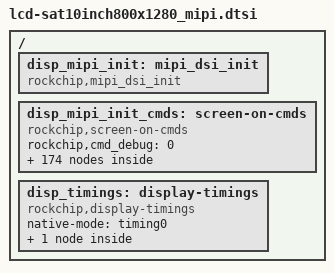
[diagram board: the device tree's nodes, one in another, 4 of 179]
/*
 * lcd model: fhd L7057ARRP051A
 * resolution: 1080 X 1920
 */
/*
 * arch/arm/boot/dts/lcd-sat10inch800x1280_mipi.dtsi
 * author: daniel
 * create date: 2017-05-26
 * lcd model: sat0101cp40I28R1-JD9366 
 * resolution: 800X1280
 * mipi channel: 4
 */
/ {
    /* about mipi */
    disp_mipi_init: mipi_dsi_init{
        compatible = "rockchip,mipi_dsi_init";
        rockchip,screen_init    = <1>;
        rockchip,dsi_lane       = <4>;
        rockchip,dsi_hs_clk     = <480>;
        rockchip,mipi_dsi_num   = <1>;
    };

/*
    disp_mipi_power_ctr: mipi_power_ctr {
        compatible = "rockchip,mipi_power_ctr";
        mipi_lcd_en:mipi_lcd_en {
                compatible = "rockchip,lcd_en";
                rockchip,gpios = <&gpio2 GPIO_B7 GPIO_ACTIVE_HIGH>;
                rockchip,delay = <20>;
        };
 
        mipi_lcd_rst:mipi_lcd_rst{
                compatible = "rockchip,lcd_rst";
                rockchip,gpios = <&gpio2 GPIO_B5 GPIO_ACTIVE_HIGH>;
                rockchip,delay = <50>;
        };
 
    };
    */

 	disp_mipi_init_cmds: screen-on-cmds {
			rockchip,cmd_debug = <0>;
			compatible = "rockchip,screen-on-cmds";
	         rockchip,on-cmds1{                                      
                                         compatible = "rockchip,on-cmds";  
                                         rockchip,cmd_type = <0x01>;     
                                         rockchip,dsi_id = <0>;          
                                         rockchip,cmd = <0x15 0xE0 0x00>;
                                         rockchip,cmd_delay = <0>;       
                                  };                                     
                 rockchip,on-cmds2{                                      
                                         compatible = "rockchip,on-cmds";  
                                         rockchip,cmd_type = <0x01>;     
                                         rockchip,dsi_id = <0>;          
                                         rockchip,cmd = <0x15 0xE1 0x93>;
                                         rockchip,cmd_delay = <0>;       
                                  };                                     
                 rockchip,on-cmds3{                                      
                                         compatible = "rockchip,on-cmds";  
                                         rockchip,cmd_type = <0x01>;     
                                         rockchip,dsi_id = <0>;          
                                         rockchip,cmd = <0x15 0xE2 0x65>;
                                         rockchip,cmd_delay = <0>;       
                                  };                                     
                 rockchip,on-cmds4{                                      
                                         compatible = "rockchip,on-cmds";  
                                         rockchip,cmd_type = <0x01>;     
                                         rockchip,dsi_id = <0>;          
                                         rockchip,cmd = <0x15 0xE3 0xF8>;
                                         rockchip,cmd_delay = <0>;       
                                  };                                     
                 rockchip,on-cmds5{                                      
                                         compatible = "rockchip,on-cmds";  
                                         rockchip,cmd_type = <0x01>;     
                                         rockchip,dsi_id = <0>;          
                                         rockchip,cmd = <0x15 0x80 0x03>;
                                         rockchip,cmd_delay = <0>;       
                                  };                                     
                 rockchip,on-cmds6{                                      
                                         compatible = "rockchip,on-cmds";  
                                         rockchip,cmd_type = <0x01>;     
                                         rockchip,dsi_id = <0>;          
                                         rockchip,cmd = <0x15 0xE0 0x04>;
                                         rockchip,cmd_delay = <0>;       
                                  };                                     
                 rockchip,on-cmds7{                                      
                                         compatible = "rockchip,on-cmds";  
                                         rockchip,cmd_type = <0x01>;     
                                         rockchip,dsi_id = <0>;          
                                         rockchip,cmd = <0x15 0x2D 0x03>;
                                         rockchip,cmd_delay = <0>;       
                                  };                                     
                 rockchip,on-cmds8{                                      
                                         compatible = "rockchip,on-cmds";  
                                         rockchip,cmd_type = <0x01>;     
                                         rockchip,dsi_id = <0>;          
                                         rockchip,cmd = <0x15 0x09 0x10>;
                                         rockchip,cmd_delay = <0>;       
                                  };  
	        rockchip,on-cmds175{                                      
                                         compatible = "rockchip,on-cmds";  
                                         rockchip,cmd_type = <0x01>;     
                                         rockchip,dsi_id = <0>;          
                                         rockchip,cmd = <0x15 0xE0 0x00>;
                                         rockchip,cmd_delay = <0>;       
                                  };                                     
                 rockchip,on-cmds9{                                      
                                         compatible = "rockchip,on-cmds";  
                                         rockchip,cmd_type = <0x01>;     
                                         rockchip,dsi_id = <0>;          
                                         rockchip,cmd = <0x15 0x70 0x10>;
                                         rockchip,cmd_delay = <0>;       
                                  };                                     
                 rockchip,on-cmds10{                                     
                                         compatible = "rockchip,on-cmds";  
                                         rockchip,cmd_type = <0x01>;     
                                         rockchip,dsi_id = <0>;          
                                         rockchip,cmd = <0x15 0x71 0x13>;
                                         rockchip,cmd_delay = <0>;       
                                  };                                     
                 rockchip,on-cmds11{                                     
                                         compatible = "rockchip,on-cmds";  
                                         rockchip,cmd_type = <0x01>;     
                                         rockchip,dsi_id = <0>;          
                                         rockchip,cmd = <0x15 0x72 0x06>;
                                         rockchip,cmd_delay = <0>;       
                                  };                                     
                 rockchip,on-cmds12{                                     
                                         compatible = "rockchip,on-cmds";  
                                         rockchip,cmd_type = <0x01>;     
                                         rockchip,dsi_id = <0>;          
                                         rockchip,cmd = <0x15 0xE0 0x02>;
                                         rockchip,cmd_delay = <0>;       
                                  };                                     
                 rockchip,on-cmds13{                                     
                                         compatible = "rockchip,on-cmds";  
                                         rockchip,cmd_type = <0x01>;     
                                         rockchip,dsi_id = <0>;          
                                         rockchip,cmd = <0x15 0x00 0x09>;
                                         rockchip,cmd_delay = <0>;       
                                  };                                     
                 rockchip,on-cmds14{                                     
                                         compatible = "rockchip,on-cmds";  
                                         rockchip,cmd_type = <0x01>;     
                                         rockchip,dsi_id = <0>;          
                                         rockchip,cmd = <0x15 0x01 0x05>;
                                         rockchip,cmd_delay = <0>;       
                                  };                                     
                 rockchip,on-cmds15{                                     
                                         compatible = "rockchip,on-cmds";  
                                         rockchip,cmd_type = <0x01>;     
                                         rockchip,dsi_id = <0>;          
                                         rockchip,cmd = <0x15 0x02 0x08>;
                                         rockchip,cmd_delay = <0>;       
                                  };                                     
                 rockchip,on-cmds16{                                     
                                         compatible = "rockchip,on-cmds";  
                                         rockchip,cmd_type = <0x01>;     
                                         rockchip,dsi_id = <0>;          
                                         rockchip,cmd = <0x15 0x03 0x04>;
                                         rockchip,cmd_delay = <0>;       
                                  };                                     
                 rockchip,on-cmds17{                                     
                                         compatible = "rockchip,on-cmds";  
                                         rockchip,cmd_type = <0x01>;     
                                         rockchip,dsi_id = <0>;          
                                         rockchip,cmd = <0x15 0x04 0x06>;
                                         rockchip,cmd_delay = <0>;       
                                  };                                     
                 rockchip,on-cmds18{                                     
                                         compatible = "rockchip,on-cmds";  
                                         rockchip,cmd_type = <0x01>;     
                                         rockchip,dsi_id = <0>;          
                                         rockchip,cmd = <0x15 0x05 0x0A>;
                                         rockchip,cmd_delay = <0>;       
                                  };                                     
                 rockchip,on-cmds19{                                     
                                         compatible = "rockchip,on-cmds";  
                                         rockchip,cmd_type = <0x01>;     
                                         rockchip,dsi_id = <0>;          
                                         rockchip,cmd = <0x15 0x06 0x07>;
                                         rockchip,cmd_delay = <0>;       
                                  };                                     
                 rockchip,on-cmds20{                                     
                                         compatible = "rockchip,on-cmds";  
                                         rockchip,cmd_type = <0x01>;     
                                         rockchip,dsi_id = <0>;          
                                         rockchip,cmd = <0x15 0x07 0x0B>;
                                         rockchip,cmd_delay = <0>;       
                                  };                                     
                 rockchip,on-cmds21{                                     
                                         compatible = "rockchip,on-cmds";  
                                         rockchip,cmd_type = <0x01>;     
                                         rockchip,dsi_id = <0>;          
                                         rockchip,cmd = <0x15 0x08 0x00>;
                                         rockchip,cmd_delay = <0>;       
                                  };                                     
                 rockchip,on-cmds22{                                     
                                         compatible = "rockchip,on-cmds";  
                                         rockchip,cmd_type = <0x01>;     
                                         rockchip,dsi_id = <0>;          
                                         rockchip,cmd = <0x15 0x09 0x1F>;
                                         rockchip,cmd_delay = <0>;       
                                  };                                     
                 rockchip,on-cmds23{                                     
                                         compatible = "rockchip,on-cmds";  
                                         rockchip,cmd_type = <0x01>;     
                                         rockchip,dsi_id = <0>;          
                                         rockchip,cmd = <0x15 0x0A 0x1F>;
                                         rockchip,cmd_delay = <0>;       
                                  };                                     
                 rockchip,on-cmds24{                                     
                                         compatible = "rockchip,on-cmds";  
                                         rockchip,cmd_type = <0x01>;     
                                         rockchip,dsi_id = <0>;          
                                         rockchip,cmd = <0x15 0x0C 0x1F>;
                                         rockchip,cmd_delay = <0>;       
                                  };                                     
                 rockchip,on-cmds25{                                     
                                         compatible = "rockchip,on-cmds";  
                                         rockchip,cmd_type = <0x01>;     
                                         rockchip,dsi_id = <0>;          
                                         rockchip,cmd = <0x15 0x0D 0x1F>;
                                         rockchip,cmd_delay = <0>;       
                                  };                                     
                 rockchip,on-cmds26{                                     
                                         compatible = "rockchip,on-cmds";  
                                         rockchip,cmd_type = <0x01>;     
                                         rockchip,dsi_id = <0>;          
                                         rockchip,cmd = <0x15 0x0E 0x1F>;
                                         rockchip,cmd_delay = <0>;       
                                  };                                     
                 rockchip,on-cmds27{                                     
                                         compatible = "rockchip,on-cmds";  
                                         rockchip,cmd_type = <0x01>;     
                                         rockchip,dsi_id = <0>;          
                                         rockchip,cmd = <0x15 0x0F 0x17>;
                                         rockchip,cmd_delay = <0>;       
                                  };                                     
                 rockchip,on-cmds28{                                     
                                         compatible = "rockchip,on-cmds";  
                                         rockchip,cmd_type = <0x01>;     
                                         rockchip,dsi_id = <0>;          
                                         rockchip,cmd = <0x15 0x10 0x37>;
                                         rockchip,cmd_delay = <0>;       
                                  };                                     
                 rockchip,on-cmds29{                                     
                                         compatible = "rockchip,on-cmds";  
                                         rockchip,cmd_type = <0x01>;     
                                         rockchip,dsi_id = <0>;          
                                         rockchip,cmd = <0x15 0x11 0x1F>;
                                         rockchip,cmd_delay = <0>;       
                                  };                                     
                 rockchip,on-cmds30{                                     
                                         compatible = "rockchip,on-cmds";  
                                         rockchip,cmd_type = <0x01>;     
                                         rockchip,dsi_id = <0>;          
                                         rockchip,cmd = <0x15 0x12 0x1F>;
                                         rockchip,cmd_delay = <0>;       
                                  };                                     
                 rockchip,on-cmds31{                                     
                                         compatible = "rockchip,on-cmds";  
                                         rockchip,cmd_type = <0x01>;     
                                         rockchip,dsi_id = <0>;          
                                         rockchip,cmd = <0x15 0x13 0x1E>;
                                         rockchip,cmd_delay = <0>;       
                                  };                                     
                 rockchip,on-cmds32{                                     
                                         compatible = "rockchip,on-cmds";  
                                         rockchip,cmd_type = <0x01>;     
                                         rockchip,dsi_id = <0>;          
                                         rockchip,cmd = <0x15 0x14 0x10>;
                                         rockchip,cmd_delay = <0>;       
                                  };                                     
                 rockchip,on-cmds33{                                     
                                         compatible = "rockchip,on-cmds";  
                                         rockchip,cmd_type = <0x01>;     
                                         rockchip,dsi_id = <0>;          
                                         rockchip,cmd = <0x15 0x15 0x1F>;
                                         rockchip,cmd_delay = <0>;       
                                  };                                     
                 rockchip,on-cmds34{                                     
                                         compatible = "rockchip,on-cmds";  
                                         rockchip,cmd_type = <0x01>;     
                                         rockchip,dsi_id = <0>;          
                                         rockchip,cmd = <0x15 0x16 0x09>;
                                         rockchip,cmd_delay = <0>;       
                                  };                                     
                 rockchip,on-cmds35{                                     
                                         compatible = "rockchip,on-cmds";  
                                         rockchip,cmd_type = <0x01>;     
                                         rockchip,dsi_id = <0>;          
                                         rockchip,cmd = <0x15 0x17 0x05>;
                                         rockchip,cmd_delay = <0>;       
                                  };                                     
                 rockchip,on-cmds36{                                     
                                         compatible = "rockchip,on-cmds";  
                                         rockchip,cmd_type = <0x01>;     
                                         rockchip,dsi_id = <0>;          
                                         rockchip,cmd = <0x15 0x18 0x08>;
                                         rockchip,cmd_delay = <0>;       
                                  };                                     
                 rockchip,on-cmds37{                                     
                                         compatible = "rockchip,on-cmds";  
                                         rockchip,cmd_type = <0x01>;     
                                         rockchip,dsi_id = <0>;          
                                         rockchip,cmd = <0x15 0x19 0x04>;
                                         rockchip,cmd_delay = <0>;       
                                  };                                     
                 rockchip,on-cmds38{                                     
                                         compatible = "rockchip,on-cmds";  
                                         rockchip,cmd_type = <0x01>;     
                                         rockchip,dsi_id = <0>;          
                                         rockchip,cmd = <0x15 0x1A 0x06>;
                                         rockchip,cmd_delay = <0>;       
                                  };                                     
                 rockchip,on-cmds39{                                     
                                         compatible = "rockchip,on-cmds";  
                                         rockchip,cmd_type = <0x01>;     
                                         rockchip,dsi_id = <0>;          
                                         rockchip,cmd = <0x15 0x1B 0x0A>;
                                         rockchip,cmd_delay = <0>;       
                                  };                                     
                 rockchip,on-cmds40{                                     
                                         compatible = "rockchip,on-cmds";  
                                         rockchip,cmd_type = <0x01>;     
                                         rockchip,dsi_id = <0>;          
                                         rockchip,cmd = <0x15 0x1C 0x07>;
                                         rockchip,cmd_delay = <0>;       
                                  };                                     
                 rockchip,on-cmds41{                                     
                                         compatible = "rockchip,on-cmds";  
                                         rockchip,cmd_type = <0x01>;     
                                         rockchip,dsi_id = <0>;          
                                         rockchip,cmd = <0x15 0x1D 0x0B>;
                                         rockchip,cmd_delay = <0>;       
                                  };                                     
                 rockchip,on-cmds42{                                     
                                         compatible = "rockchip,on-cmds";  
                                         rockchip,cmd_type = <0x01>;     
                                         rockchip,dsi_id = <0>;          
                                         rockchip,cmd = <0x15 0x1E 0x00>;
                                         rockchip,cmd_delay = <0>;       
                                  };                                     
                 rockchip,on-cmds43{                                     
                                         compatible = "rockchip,on-cmds";  
                                         rockchip,cmd_type = <0x01>;     
                                         rockchip,dsi_id = <0>;          
                                         rockchip,cmd = <0x15 0x1F 0x1F>;
                                         rockchip,cmd_delay = <0>;       
                                  };                                     
                 rockchip,on-cmds44{                                     
                                         compatible = "rockchip,on-cmds";  
                                         rockchip,cmd_type = <0x01>;     
                                         rockchip,dsi_id = <0>;          
                                         rockchip,cmd = <0x15 0x20 0x1F>;
                                         rockchip,cmd_delay = <0>;       
                                  };                                     
                 rockchip,on-cmds45{                                     
                                         compatible = "rockchip,on-cmds";  
                                         rockchip,cmd_type = <0x01>;     
                                         rockchip,dsi_id = <0>;          
                                         rockchip,cmd = <0x15 0x21 0x1F>;
                                         rockchip,cmd_delay = <0>;       
                                  };                                     
                 rockchip,on-cmds46{                                     
                                         compatible = "rockchip,on-cmds";  
                                         rockchip,cmd_type = <0x01>;     
                                         rockchip,dsi_id = <0>;          
                                         rockchip,cmd = <0x15 0x22 0x1F>;
                                         rockchip,cmd_delay = <0>;       
                                  };                                     
                 rockchip,on-cmds47{                                     
                                         compatible = "rockchip,on-cmds";  
                                         rockchip,cmd_type = <0x01>;     
                                         rockchip,dsi_id = <0>;          
                                         rockchip,cmd = <0x15 0x23 0x1F>;
                                         rockchip,cmd_delay = <0>;       
                                  };                                     
                 rockchip,on-cmds48{                                     
                                         compatible = "rockchip,on-cmds";  
                                         rockchip,cmd_type = <0x01>;     
                                         rockchip,dsi_id = <0>;          
                                         rockchip,cmd = <0x15 0x24 0x1F>;
                                         rockchip,cmd_delay = <0>;       
                                  };                                     
                 rockchip,on-cmds49{                                     
                                         compatible = "rockchip,on-cmds";  
                                         rockchip,cmd_type = <0x01>;     
                                         rockchip,dsi_id = <0>;          
                                         rockchip,cmd = <0x15 0x25 0x17>;
                                         rockchip,cmd_delay = <0>;       
                                  };                                     
                 rockchip,on-cmds50{                                     
                                         compatible = "rockchip,on-cmds";  
                                         rockchip,cmd_type = <0x01>;     
                                         rockchip,dsi_id = <0>;          
                                         rockchip,cmd = <0x15 0x26 0x37>;
                                         rockchip,cmd_delay = <0>;       
                                  };                                     
                 rockchip,on-cmds51{                                     
                                         compatible = "rockchip,on-cmds";  
                                         rockchip,cmd_type = <0x01>;     
                                         rockchip,dsi_id = <0>;          
                                         rockchip,cmd = <0x15 0x27 0x1F>;
                                         rockchip,cmd_delay = <0>;       
                                  };                                     
                 rockchip,on-cmds52{                                     
                                         compatible = "rockchip,on-cmds";  
                                         rockchip,cmd_type = <0x01>;     
                                         rockchip,dsi_id = <0>;          
                                         rockchip,cmd = <0x15 0x28 0x1F>;
                                         rockchip,cmd_delay = <0>;       
                                  };                                     
                 rockchip,on-cmds53{                                     
                                         compatible = "rockchip,on-cmds";  
                                         rockchip,cmd_type = <0x01>;     
                                         rockchip,dsi_id = <0>;          
                                         rockchip,cmd = <0x15 0x29 0x1E>;
                                         rockchip,cmd_delay = <0>;       
                                  };                                     
                 rockchip,on-cmds54{                                     
                                         compatible = "rockchip,on-cmds";  
                                         rockchip,cmd_type = <0x01>;     
                                         rockchip,dsi_id = <0>;          
                                         rockchip,cmd = <0x15 0x2A 0x10>;
                                         rockchip,cmd_delay = <0>;       
                                  };                                     
                 rockchip,on-cmds55{                                     
                                         compatible = "rockchip,on-cmds";  
                                         rockchip,cmd_type = <0x01>;     
                                         rockchip,dsi_id = <0>;          
                                         rockchip,cmd = <0x15 0x2B 0x1F>;
                                         rockchip,cmd_delay = <0>;       
                                  };                                     
                 rockchip,on-cmds56{                                     
                                         compatible = "rockchip,on-cmds";  
                                         rockchip,cmd_type = <0x01>;     
                                         rockchip,dsi_id = <0>;          
                                         rockchip,cmd = <0x15 0x58 0x01>;
                                         rockchip,cmd_delay = <0>;       
                                  };                                     
                 rockchip,on-cmds57{                                     
                                         compatible = "rockchip,on-cmds";  
                                         rockchip,cmd_type = <0x01>;     
                                         rockchip,dsi_id = <0>;          
                                         rockchip,cmd = <0x15 0x59 0x00>;
                                         rockchip,cmd_delay = <0>;       
                                  };                                     
                 rockchip,on-cmds58{                                     
                                         compatible = "rockchip,on-cmds";  
                                         rockchip,cmd_type = <0x01>;     
                                         rockchip,dsi_id = <0>;          
                                         rockchip,cmd = <0x15 0x5A 0x00>;
                                         rockchip,cmd_delay = <0>;       
                                  };                                     
                 rockchip,on-cmds59{                                     
                                         compatible = "rockchip,on-cmds";  
                                         rockchip,cmd_type = <0x01>;     
                                         rockchip,dsi_id = <0>;          
                                         rockchip,cmd = <0x15 0x5B 0x00>;
                                         rockchip,cmd_delay = <0>;       
                                  };                                     
                 rockchip,on-cmds60{                                     
                                         compatible = "rockchip,on-cmds";  
                                         rockchip,cmd_type = <0x01>;     
                                         rockchip,dsi_id = <0>;          
                                         rockchip,cmd = <0x15 0x5C 0x01>;
                                         rockchip,cmd_delay = <0>;       
                                  };                                     
                 rockchip,on-cmds61{                                     
                                         compatible = "rockchip,on-cmds";  
                                         rockchip,cmd_type = <0x01>;     
                                         rockchip,dsi_id = <0>;          
                                         rockchip,cmd = <0x15 0x5D 0x70>;
                                         rockchip,cmd_delay = <0>;       
                                  };                                     
                 rockchip,on-cmds62{                                     
                                         compatible = "rockchip,on-cmds";  
                                         rockchip,cmd_type = <0x01>;     
                                         rockchip,dsi_id = <0>;          
                                         rockchip,cmd = <0x15 0x5E 0x00>;
                                         rockchip,cmd_delay = <0>;       
                                  };                                     
                 rockchip,on-cmds63{                                     
                                         compatible = "rockchip,on-cmds";  
                                         rockchip,cmd_type = <0x01>;     
                                         rockchip,dsi_id = <0>;          
                                         rockchip,cmd = <0x15 0x5F 0x00>;
                                         rockchip,cmd_delay = <0>;       
                                  };                                     
                 rockchip,on-cmds64{                                     
                                         compatible = "rockchip,on-cmds";  
                                         rockchip,cmd_type = <0x01>;     
                                         rockchip,dsi_id = <0>;          
                                         rockchip,cmd = <0x15 0x60 0x40>;
                                         rockchip,cmd_delay = <0>;       
                                  };                                     
                 rockchip,on-cmds65{                                     
                                         compatible = "rockchip,on-cmds";  
                                         rockchip,cmd_type = <0x01>;     
                                         rockchip,dsi_id = <0>;          
                                         rockchip,cmd = <0x15 0x61 0x00>;
                                         rockchip,cmd_delay = <0>;       
                                  };                                     
                 rockchip,on-cmds66{                                     
                                         compatible = "rockchip,on-cmds";  
                                         rockchip,cmd_type = <0x01>;     
                                         rockchip,dsi_id = <0>;          
                                         rockchip,cmd = <0x15 0x62 0x00>;
                                         rockchip,cmd_delay = <0>;       
                                  };                                     
                 rockchip,on-cmds67{                                     
                                         compatible = "rockchip,on-cmds";  
                                         rockchip,cmd_type = <0x01>;     
                                         rockchip,dsi_id = <0>;          
                                         rockchip,cmd = <0x15 0x63 0x65>;
                                         rockchip,cmd_delay = <0>;       
                                  };                                     
                 rockchip,on-cmds68{                                     
                                         compatible = "rockchip,on-cmds";  
                                         rockchip,cmd_type = <0x01>;     
                                         rockchip,dsi_id = <0>;          
                                         rockchip,cmd = <0x15 0x64 0x65>;
                                         rockchip,cmd_delay = <0>;       
                                  };                                     
                 rockchip,on-cmds69{                                     
                                         compatible = "rockchip,on-cmds";  
                                         rockchip,cmd_type = <0x01>;     
                                         rockchip,dsi_id = <0>;          
                                         rockchip,cmd = <0x15 0x65 0x45>;
                                         rockchip,cmd_delay = <0>;       
                                  };                                     
                 rockchip,on-cmds70{                                     
                                         compatible = "rockchip,on-cmds";  
                                         rockchip,cmd_type = <0x01>;     
                                         rockchip,dsi_id = <0>;          
                                         rockchip,cmd = <0x15 0x66 0x09>;
                                         rockchip,cmd_delay = <0>;       
                                  };                                     
                 rockchip,on-cmds71{                                     
                                         compatible = "rockchip,on-cmds";  
                                         rockchip,cmd_type = <0x01>;     
                                         rockchip,dsi_id = <0>;          
                                         rockchip,cmd = <0x15 0x67 0x73>;
                                         rockchip,cmd_delay = <0>;       
                                  };                                     
                 rockchip,on-cmds72{                                     
                                         compatible = "rockchip,on-cmds";  
                                         rockchip,cmd_type = <0x01>;     
                                         rockchip,dsi_id = <0>;          
                                         rockchip,cmd = <0x15 0x68 0x05>;
                                         rockchip,cmd_delay = <0>;       
                                  };                                     
                 rockchip,on-cmds73{                                     
                                         compatible = "rockchip,on-cmds";  
                                         rockchip,cmd_type = <0x01>;     
                                         rockchip,dsi_id = <0>;          
                                         rockchip,cmd = <0x15 0x69 0x00>;
                                         rockchip,cmd_delay = <0>;       
                                  };                                     
                 rockchip,on-cmds74{                                     
                                         compatible = "rockchip,on-cmds";  
                                         rockchip,cmd_type = <0x01>;     
                                         rockchip,dsi_id = <0>;          
                                         rockchip,cmd = <0x15 0x6A 0x64>;
                                         rockchip,cmd_delay = <0>;       
                                  };                                     
                 rockchip,on-cmds75{                                     
                                         compatible = "rockchip,on-cmds";  
                                         rockchip,cmd_type = <0x01>;     
                                         rockchip,dsi_id = <0>;          
                                         rockchip,cmd = <0x15 0x6B 0x00>;
                                         rockchip,cmd_delay = <0>;       
                                  };                                     
                 rockchip,on-cmds76{                                     
                                         compatible = "rockchip,on-cmds";  
                                         rockchip,cmd_type = <0x01>;     
                                         rockchip,dsi_id = <0>;          
                                         rockchip,cmd = <0x15 0x6C 0x00>;
                                         rockchip,cmd_delay = <0>;       
                                  };                                     
                 rockchip,on-cmds77{                                     
                                         compatible = "rockchip,on-cmds";  
                                         rockchip,cmd_type = <0x01>;     
                                         rockchip,dsi_id = <0>;          
                                         rockchip,cmd = <0x15 0x6D 0x00>;
                                         rockchip,cmd_delay = <0>;       
                                  };                                     
                 rockchip,on-cmds78{                                     
                                         compatible = "rockchip,on-cmds";  
                                         rockchip,cmd_type = <0x01>;     
                                         rockchip,dsi_id = <0>;          
                                         rockchip,cmd = <0x15 0x6E 0x00>;
                                         rockchip,cmd_delay = <0>;       
                                  };                                     
                 rockchip,on-cmds79{                                     
                                         compatible = "rockchip,on-cmds";  
                                         rockchip,cmd_type = <0x01>;     
                                         rockchip,dsi_id = <0>;          
                                         rockchip,cmd = <0x15 0x6F 0x88>;
                                         rockchip,cmd_delay = <0>;       
                                  };                                     
                 rockchip,on-cmds80{                                     
                                         compatible = "rockchip,on-cmds";  
                                         rockchip,cmd_type = <0x01>;     
                                         rockchip,dsi_id = <0>;          
                                         rockchip,cmd = <0x15 0x70 0x00>;
                                         rockchip,cmd_delay = <0>;       
                                  };                                     
                 rockchip,on-cmds81{                                     
                                         compatible = "rockchip,on-cmds";  
                                         rockchip,cmd_type = <0x01>;     
                                         rockchip,dsi_id = <0>;          
                                         rockchip,cmd = <0x15 0x71 0x00>;
                                         rockchip,cmd_delay = <0>;       
                                  };                                     
                 rockchip,on-cmds82{                                     
                                         compatible = "rockchip,on-cmds";  
                                         rockchip,cmd_type = <0x01>;     
                                         rockchip,dsi_id = <0>;          
                                         rockchip,cmd = <0x15 0x72 0x06>;
                                         rockchip,cmd_delay = <0>;       
                                  };                                     
                 rockchip,on-cmds83{                                     
                                         compatible = "rockchip,on-cmds";  
                                         rockchip,cmd_type = <0x01>;     
                                         rockchip,dsi_id = <0>;          
                                         rockchip,cmd = <0x15 0x73 0x7B>;
                                         rockchip,cmd_delay = <0>;       
                                  };                                     
                 rockchip,on-cmds84{                                     
                                         compatible = "rockchip,on-cmds";  
                                         rockchip,cmd_type = <0x01>;     
                                         rockchip,dsi_id = <0>;          
                                         rockchip,cmd = <0x15 0x74 0x00>;
                                         rockchip,cmd_delay = <0>;       
                                  };                                     
                 rockchip,on-cmds85{                                     
                                         compatible = "rockchip,on-cmds";  
                                         rockchip,cmd_type = <0x01>;     
                                         rockchip,dsi_id = <0>;          
                                         rockchip,cmd = <0x15 0x75 0x80>;
                                         rockchip,cmd_delay = <0>;       
                                  };                                     
                 rockchip,on-cmds86{                                     
                                         compatible = "rockchip,on-cmds";  
                                         rockchip,cmd_type = <0x01>;     
                                         rockchip,dsi_id = <0>;          
                                         rockchip,cmd = <0x15 0x76 0x00>;
                                         rockchip,cmd_delay = <0>;       
                                  };                                     
                 rockchip,on-cmds87{                                     
                                         compatible = "rockchip,on-cmds";  
                                         rockchip,cmd_type = <0x01>;     
                                         rockchip,dsi_id = <0>;          
                                         rockchip,cmd = <0x15 0x77 0x05>;
                                         rockchip,cmd_delay = <0>;       
                                  };                                     
                 rockchip,on-cmds88{                                     
                                         compatible = "rockchip,on-cmds";  
                                         rockchip,cmd_type = <0x01>;     
                                         rockchip,dsi_id = <0>;          
                                         rockchip,cmd = <0x15 0x78 0x18>;
                                         rockchip,cmd_delay = <0>;       
                                  };                                     
                 rockchip,on-cmds89{                                     
                                         compatible = "rockchip,on-cmds";  
                                         rockchip,cmd_type = <0x01>;     
                                         rockchip,dsi_id = <0>;          
                                         rockchip,cmd = <0x15 0x79 0x00>;
                                         rockchip,cmd_delay = <0>;       
                                  };                                     
                 rockchip,on-cmds90{                                     
                                         compatible = "rockchip,on-cmds";  
                                         rockchip,cmd_type = <0x01>;     
                                         rockchip,dsi_id = <0>;          
                                         rockchip,cmd = <0x15 0x7A 0x00>;
                                         rockchip,cmd_delay = <0>;       
                                  };                                     
                 rockchip,on-cmds91{                                     
                                         compatible = "rockchip,on-cmds";  
                                         rockchip,cmd_type = <0x01>;     
                                         rockchip,dsi_id = <0>;          
                                         rockchip,cmd = <0x15 0x7B 0x00>;
                                         rockchip,cmd_delay = <0>;       
                                  };                                     
                 rockchip,on-cmds92{                                     
                                         compatible = "rockchip,on-cmds";  
                                         rockchip,cmd_type = <0x01>;     
                                         rockchip,dsi_id = <0>;          
                                         rockchip,cmd = <0x15 0x7C 0x00>;
                                         rockchip,cmd_delay = <0>;       
                                  };                                     
                 rockchip,on-cmds93{                                     
                                         compatible = "rockchip,on-cmds";  
                                         rockchip,cmd_type = <0x01>;     
                                         rockchip,dsi_id = <0>;          
                                         rockchip,cmd = <0x15 0x7D 0x03>;
                                         rockchip,cmd_delay = <0>;       
                                  };                                     
                 rockchip,on-cmds94{                                     
                                         compatible = "rockchip,on-cmds";  
                                         rockchip,cmd_type = <0x01>;     
                                         rockchip,dsi_id = <0>;          
                                         rockchip,cmd = <0x15 0x7E 0x7B>;
                                         rockchip,cmd_delay = <0>;       
                                  };                                     
                 rockchip,on-cmds95{                                     
                                         compatible = "rockchip,on-cmds";  
                                         rockchip,cmd_type = <0x01>;     
                                         rockchip,dsi_id = <0>;          
                                         rockchip,cmd = <0x15 0xE0 0x01>;
                                         rockchip,cmd_delay = <0>;       
                                  };                                     
                 rockchip,on-cmds96{                                     
                                         compatible = "rockchip,on-cmds";  
                                         rockchip,cmd_type = <0x01>;     
                                         rockchip,dsi_id = <0>;          
                                         rockchip,cmd = <0x15 0x00 0x00>;
                                         rockchip,cmd_delay = <0>;       
                                  };                                     
                 rockchip,on-cmds97{                                     
                                         compatible = "rockchip,on-cmds";  
                                         rockchip,cmd_type = <0x01>;     
                                         rockchip,dsi_id = <0>;          
                                         rockchip,cmd = <0x15 0x01 0x7B>;
                                         rockchip,cmd_delay = <0>;       
                                  };                                     
                 rockchip,on-cmds98{                                     
                                         compatible = "rockchip,on-cmds";  
                                         rockchip,cmd_type = <0x01>;     
                                         rockchip,dsi_id = <0>;          
                                         rockchip,cmd = <0x15 0x17 0x00>;
                                         rockchip,cmd_delay = <0>;       
                                  };                                     
                 rockchip,on-cmds99{                                     
                                         compatible = "rockchip,on-cmds";  
                                         rockchip,cmd_type = <0x01>;     
                                         rockchip,dsi_id = <0>;          
                                         rockchip,cmd = <0x15 0x18 0xC2>;
                                         rockchip,cmd_delay = <0>;       
                                  };                                     
                 rockchip,on-cmds100{                                    
                                         compatible = "rockchip,on-cmds";  
                                         rockchip,cmd_type = <0x01>;     
                                         rockchip,dsi_id = <0>;          
                                         rockchip,cmd = <0x15 0x19 0x01>;
                                         rockchip,cmd_delay = <0>;       
                                  };                                     
                 rockchip,on-cmds101{                                    
                                         compatible = "rockchip,on-cmds";  
                                         rockchip,cmd_type = <0x01>;     
                                         rockchip,dsi_id = <0>;          
                                         rockchip,cmd = <0x15 0x1A 0x00>;
                                         rockchip,cmd_delay = <0>;       
                                  };                                     
                 rockchip,on-cmds102{                                    
                                         compatible = "rockchip,on-cmds";  
                                         rockchip,cmd_type = <0x01>;     
                                         rockchip,dsi_id = <0>;          
                                         rockchip,cmd = <0x15 0x1B 0xC2>;
                                         rockchip,cmd_delay = <0>;       
                                  };                                     
                 rockchip,on-cmds103{                                    
                                         compatible = "rockchip,on-cmds";  
                                         rockchip,cmd_type = <0x01>;     
                                         rockchip,dsi_id = <0>;          
                                         rockchip,cmd = <0x15 0x1C 0x01>;
                                         rockchip,cmd_delay = <0>;       
                                  };                                     
                 rockchip,on-cmds104{                                    
                                         compatible = "rockchip,on-cmds";  
                                         rockchip,cmd_type = <0x01>;     
                                         rockchip,dsi_id = <0>;          
                                         rockchip,cmd = <0x15 0x1F 0x3F>;
                                         rockchip,cmd_delay = <0>;       
                                  };                                     
                 rockchip,on-cmds105{                                    
                                         compatible = "rockchip,on-cmds";  
                                         rockchip,cmd_type = <0x01>;     
                                         rockchip,dsi_id = <0>;          
                                         rockchip,cmd = <0x15 0x20 0x24>;
                                         rockchip,cmd_delay = <0>;       
                                  };                                     
                 rockchip,on-cmds106{                                    
                                         compatible = "rockchip,on-cmds";  
                                         rockchip,cmd_type = <0x01>;     
                                         rockchip,dsi_id = <0>;          
                                         rockchip,cmd = <0x15 0x21 0x24>;
                                         rockchip,cmd_delay = <0>;       
                                  };                                     
                 rockchip,on-cmds107{                                    
                                         compatible = "rockchip,on-cmds";  
                                         rockchip,cmd_type = <0x01>;     
                                         rockchip,dsi_id = <0>;          
                                         rockchip,cmd = <0x15 0x22 0x0E>;
                                         rockchip,cmd_delay = <0>;       
                                  };                                     
                 rockchip,on-cmds108{                                    
                                         compatible = "rockchip,on-cmds";  
                                         rockchip,cmd_type = <0x01>;     
                                         rockchip,dsi_id = <0>;          
                                         rockchip,cmd = <0x15 0x37 0x09>;
                                         rockchip,cmd_delay = <0>;       
                                  };                                     
                 rockchip,on-cmds109{                                    
                                         compatible = "rockchip,on-cmds";  
                                         rockchip,cmd_type = <0x01>;     
                                         rockchip,dsi_id = <0>;          
                                         rockchip,cmd = <0x15 0x38 0x04>;
                                         rockchip,cmd_delay = <0>;       
                                  };                                     
                 rockchip,on-cmds110{                                    
                                         compatible = "rockchip,on-cmds";  
                                         rockchip,cmd_type = <0x01>;     
                                         rockchip,dsi_id = <0>;          
                                         rockchip,cmd = <0x15 0x39 0x00>;
                                         rockchip,cmd_delay = <0>;       
                                  };                                     
                 rockchip,on-cmds111{                                    
                                         compatible = "rockchip,on-cmds";  
                                         rockchip,cmd_type = <0x01>;     
                                         rockchip,dsi_id = <0>;          
                                         rockchip,cmd = <0x15 0x3A 0x01>;
                                         rockchip,cmd_delay = <0>;       
                                  };                                     
                 rockchip,on-cmds112{                                    
                                         compatible = "rockchip,on-cmds";  
                                         rockchip,cmd_type = <0x01>;     
                                         rockchip,dsi_id = <0>;          
                                         rockchip,cmd = <0x15 0x3C 0x78>;
                                         rockchip,cmd_delay = <0>;       
                                  };                                     
                 rockchip,on-cmds113{                                    
                                         compatible = "rockchip,on-cmds";  
                                         rockchip,cmd_type = <0x01>;     
                                         rockchip,dsi_id = <0>;          
                                         rockchip,cmd = <0x15 0x3D 0xFF>;
                                         rockchip,cmd_delay = <0>;       
                                  };                                     
                 rockchip,on-cmds114{                                    
                                         compatible = "rockchip,on-cmds";  
                                         rockchip,cmd_type = <0x01>;     
                                         rockchip,dsi_id = <0>;          
                                         rockchip,cmd = <0x15 0x3E 0xFF>;
                                         rockchip,cmd_delay = <0>;       
                                  };                                     
                 rockchip,on-cmds115{                                    
                                         compatible = "rockchip,on-cmds";  
                                         rockchip,cmd_type = <0x01>;     
                                         rockchip,dsi_id = <0>;          
                                         rockchip,cmd = <0x15 0x3F 0xFF>;
                                         rockchip,cmd_delay = <0>;       
                                  };                                     
                 rockchip,on-cmds116{                                    
                                         compatible = "rockchip,on-cmds";  
                                         rockchip,cmd_type = <0x01>;     
                                         rockchip,dsi_id = <0>;          
                                         rockchip,cmd = <0x15 0x40 0x06>;
                                         rockchip,cmd_delay = <0>;       
                                  };                                     
                 rockchip,on-cmds117{                                    
                                         compatible = "rockchip,on-cmds";  
                                         rockchip,cmd_type = <0x01>;     
                                         rockchip,dsi_id = <0>;          
                                         rockchip,cmd = <0x15 0x41 0xA0>;
                                         rockchip,cmd_delay = <0>;       
                                  };                                     
                 rockchip,on-cmds118{                                    
                                         compatible = "rockchip,on-cmds";  
                                         rockchip,cmd_type = <0x01>;     
                                         rockchip,dsi_id = <0>;          
                                         rockchip,cmd = <0x15 0x43 0x08>;
                                         rockchip,cmd_delay = <0>;       
                                  };                                     
                 rockchip,on-cmds119{                                    
                                         compatible = "rockchip,on-cmds";  
                                         rockchip,cmd_type = <0x01>;     
                                         rockchip,dsi_id = <0>;          
                                         rockchip,cmd = <0x15 0x44 0x07>;
                                         rockchip,cmd_delay = <0>;       
                                  };                                     
                 rockchip,on-cmds120{                                    
                                         compatible = "rockchip,on-cmds";  
                                         rockchip,cmd_type = <0x01>;     
                                         rockchip,dsi_id = <0>;          
                                         rockchip,cmd = <0x15 0x45 0x24>;
                                         rockchip,cmd_delay = <0>;       
                                  };                                     
                 //rockchip,on-cmds121{                                    
                                         //compatible = "rockchip,on-cmds";  
                                         //rockchip,cmd_type = <0x01>;     
                                         //rockchip,dsi_id = <0>;          
                                         //rockchip,cmd = <0x15 0x4A 0x35>;
                                         //rockchip,cmd_delay = <0>;       
                                  //};                                     
                 rockchip,on-cmds122{                                    
                                         compatible = "rockchip,on-cmds";  
                                         rockchip,cmd_type = <0x01>;     
                                         rockchip,dsi_id = <0>;          
                                         rockchip,cmd = <0x15 0x55 0x01>;
                                         rockchip,cmd_delay = <0>;       
                                  };                                     
                 rockchip,on-cmds123{                                    
                                         compatible = "rockchip,on-cmds";  
                                         rockchip,cmd_type = <0x01>;     
                                         rockchip,dsi_id = <0>;          
                                         rockchip,cmd = <0x15 0x56 0x01>;
                                         rockchip,cmd_delay = <0>;       
                                  };                                     
                 rockchip,on-cmds124{                                    
                                         compatible = "rockchip,on-cmds";  
                                         rockchip,cmd_type = <0x01>;     
                                         rockchip,dsi_id = <0>;          
                                         rockchip,cmd = <0x15 0x57 0x69>;
                                         rockchip,cmd_delay = <0>;       
                                  };                                     
                 rockchip,on-cmds125{                                    
                                         compatible = "rockchip,on-cmds";  
                                         rockchip,cmd_type = <0x01>;     
                                         rockchip,dsi_id = <0>;          
                                         rockchip,cmd = <0x15 0x58 0x0A>;
                                         rockchip,cmd_delay = <0>;       
                                  };                                     
                 rockchip,on-cmds126{                                    
                                         compatible = "rockchip,on-cmds";  
                                         rockchip,cmd_type = <0x01>;     
                                         rockchip,dsi_id = <0>;          
                                         rockchip,cmd = <0x15 0x59 0x2A>;
                                         rockchip,cmd_delay = <0>;       
                                  };                                     
                 rockchip,on-cmds127{                                    
                                         compatible = "rockchip,on-cmds";  
                                         rockchip,cmd_type = <0x01>;     
                                         rockchip,dsi_id = <0>;          
                                         rockchip,cmd = <0x15 0x5A 0x28>;
                                         rockchip,cmd_delay = <0>;       
                                  };                                                                         
                 rockchip,on-cmds128{                                    
                                         compatible = "rockchip,on-cmds";  
                                         rockchip,cmd_type = <0x01>;     
                                         rockchip,dsi_id = <0>;          
                                         rockchip,cmd = <0x15 0x5B 0x0F>;
                                         rockchip,cmd_delay = <0>;       
                                  };                                     
                 rockchip,on-cmds129{                                    
                                         compatible = "rockchip,on-cmds";  
                                         rockchip,cmd_type = <0x01>;     
                                         rockchip,dsi_id = <0>;          
                                         rockchip,cmd = <0x15 0x5D 0x7C>;
                                         rockchip,cmd_delay = <0>;       
                                  };                                     
                 rockchip,on-cmds130{                                    
                                         compatible = "rockchip,on-cmds";  
                                         rockchip,cmd_type = <0x01>;     
                                         rockchip,dsi_id = <0>;          
                                         rockchip,cmd = <0x15 0x5E 0x67>;
                                         rockchip,cmd_delay = <0>;       
                                  };                                     
                 rockchip,on-cmds131{                                    
                                         compatible = "rockchip,on-cmds";  
                                         rockchip,cmd_type = <0x01>;     
                                         rockchip,dsi_id = <0>;          
                                         rockchip,cmd = <0x15 0x5F 0x55>;
                                         rockchip,cmd_delay = <0>;       
                                  };                                     
                 rockchip,on-cmds132{                                    
                                         compatible = "rockchip,on-cmds";  
                                         rockchip,cmd_type = <0x01>;     
                                         rockchip,dsi_id = <0>;          
                                         rockchip,cmd = <0x15 0x60 0x48>;
                                         rockchip,cmd_delay = <0>;       
                                  };                                     
                 rockchip,on-cmds133{                                    
                                         compatible = "rockchip,on-cmds";  
                                         rockchip,cmd_type = <0x01>;     
                                         rockchip,dsi_id = <0>;          
                                         rockchip,cmd = <0x15 0x61 0x3E>;
                                         rockchip,cmd_delay = <0>;       
                                  };                                     
                 rockchip,on-cmds134{                                    
                                         compatible = "rockchip,on-cmds";  
                                         rockchip,cmd_type = <0x01>;     
                                         rockchip,dsi_id = <0>;          
                                         rockchip,cmd = <0x15 0x62 0x2D>;
                                         rockchip,cmd_delay = <0>;       
                                  };                                     
                 rockchip,on-cmds135{                                    
                                         compatible = "rockchip,on-cmds";  
                                         rockchip,cmd_type = <0x01>;     
                                         rockchip,dsi_id = <0>;          
                                         rockchip,cmd = <0x15 0x63 0x30>;
                                         rockchip,cmd_delay = <0>;       
                                  };                                     
                 rockchip,on-cmds136{                                    
                                         compatible = "rockchip,on-cmds";  
                                         rockchip,cmd_type = <0x01>;     
                                         rockchip,dsi_id = <0>;          
                                         rockchip,cmd = <0x15 0x64 0x16>;
                                         rockchip,cmd_delay = <0>;       
                                  };                                     
                 rockchip,on-cmds137{                                    
                                         compatible = "rockchip,on-cmds";  
                                         rockchip,cmd_type = <0x01>;     
                                         rockchip,dsi_id = <0>;          
                                         rockchip,cmd = <0x15 0x65 0x2C>;
                                         rockchip,cmd_delay = <0>;       
                                  };                                     
                 rockchip,on-cmds138{                                    
                                         compatible = "rockchip,on-cmds";  
                                         rockchip,cmd_type = <0x01>;     
                                         rockchip,dsi_id = <0>;          
                                         rockchip,cmd = <0x15 0x66 0x28>;
                                         rockchip,cmd_delay = <0>;       
                                  };                                     
                 rockchip,on-cmds139{                                    
                                         compatible = "rockchip,on-cmds";  
                                         rockchip,cmd_type = <0x01>;     
                                         rockchip,dsi_id = <0>;          
                                         rockchip,cmd = <0x15 0x67 0x26>;
                                         rockchip,cmd_delay = <0>;       
                                  };                                     
                 rockchip,on-cmds140{                                    
                                         compatible = "rockchip,on-cmds";  
                                         rockchip,cmd_type = <0x01>;     
                                         rockchip,dsi_id = <0>;          
                                         rockchip,cmd = <0x15 0x68 0x42>;
                                         rockchip,cmd_delay = <0>;       
                                  };                                     
                 rockchip,on-cmds141{                                    
                                         compatible = "rockchip,on-cmds";  
                                         rockchip,cmd_type = <0x01>;     
                                         rockchip,dsi_id = <0>;          
                                         rockchip,cmd = <0x15 0x69 0x30>;
                                         rockchip,cmd_delay = <0>;       
                                  };                                     
                 rockchip,on-cmds142{                                    
                                         compatible = "rockchip,on-cmds";  
                                         rockchip,cmd_type = <0x01>;     
                                         rockchip,dsi_id = <0>;          
                                         rockchip,cmd = <0x15 0x6A 0x38>;
                                         rockchip,cmd_delay = <0>;       
                                  };                                     
                 rockchip,on-cmds143{                                    
                                         compatible = "rockchip,on-cmds";  
                                         rockchip,cmd_type = <0x01>;     
                                         rockchip,dsi_id = <0>;          
                                         rockchip,cmd = <0x15 0x6B 0x29>;
                                         rockchip,cmd_delay = <0>;       
                                  };                                     
                 rockchip,on-cmds144{                                    
                                         compatible = "rockchip,on-cmds";  
                                         rockchip,cmd_type = <0x01>;     
                                         rockchip,dsi_id = <0>;          
                                         rockchip,cmd = <0x15 0x6C 0x26>;
                                         rockchip,cmd_delay = <0>;       
                                  };                                     
                 rockchip,on-cmds145{                                    
                                         compatible = "rockchip,on-cmds";  
                                         rockchip,cmd_type = <0x01>;     
                                         rockchip,dsi_id = <0>;          
                                         rockchip,cmd = <0x15 0x6D 0x1C>;
                                         rockchip,cmd_delay = <0>;       
                                  };                                     
                 rockchip,on-cmds146{                                    
                                         compatible = "rockchip,on-cmds";  
                                         rockchip,cmd_type = <0x01>;     
                                         rockchip,dsi_id = <0>;          
                                         rockchip,cmd = <0x15 0x6E 0x0D>;
                                         rockchip,cmd_delay = <0>;       
                                  };                                     
                 rockchip,on-cmds147{                                    
                                         compatible = "rockchip,on-cmds";  
                                         rockchip,cmd_type = <0x01>;     
                                         rockchip,dsi_id = <0>;          
                                         rockchip,cmd = <0x15 0x6F 0x00>;
                                         rockchip,cmd_delay = <0>;       
                                  };                                     
                 rockchip,on-cmds148{                                    
                                         compatible = "rockchip,on-cmds";  
                                         rockchip,cmd_type = <0x01>;     
                                         rockchip,dsi_id = <0>;          
                                         rockchip,cmd = <0x15 0x70 0x7C>;
                                         rockchip,cmd_delay = <0>;       
                                  };                                                                         
                 rockchip,on-cmds149{                                    
                                         compatible = "rockchip,on-cmds";  
                                         rockchip,cmd_type = <0x01>;     
                                         rockchip,dsi_id = <0>;          
                                         rockchip,cmd = <0x15 0x71 0x69>;
                                         rockchip,cmd_delay = <0>;       
                                  };                                     
                 rockchip,on-cmds150{                                    
                                         compatible = "rockchip,on-cmds";  
                                         rockchip,cmd_type = <0x01>;     
                                         rockchip,dsi_id = <0>;          
                                         rockchip,cmd = <0x15 0x72 0x55>;
                                         rockchip,cmd_delay = <0>;       
                                  };                                     
                 rockchip,on-cmds151{                                    
                                         compatible = "rockchip,on-cmds";  
                                         rockchip,cmd_type = <0x01>;     
                                         rockchip,dsi_id = <0>;          
                                         rockchip,cmd = <0x15 0x73 0x48>;
                                         rockchip,cmd_delay = <0>;       
                                  };                                     
                 rockchip,on-cmds152{                                    
                                         compatible = "rockchip,on-cmds";  
                                         rockchip,cmd_type = <0x01>;     
                                         rockchip,dsi_id = <0>;          
                                         rockchip,cmd = <0x15 0x74 0x3E>;
                                         rockchip,cmd_delay = <0>;       
                                  };                                                                          
                 rockchip,on-cmds153{                                    
                                         compatible = "rockchip,on-cmds";  
                                         rockchip,cmd_type = <0x01>;     
                                         rockchip,dsi_id = <0>;          
                                         rockchip,cmd = <0x15 0x75 0x2D>;
                                         rockchip,cmd_delay = <0>;       
                                  };                                     
                 rockchip,on-cmds154{                                    
                                         compatible = "rockchip,on-cmds";  
                                         rockchip,cmd_type = <0x01>;     
                                         rockchip,dsi_id = <0>;          
                                         rockchip,cmd = <0x15 0x76 0x30>;
                                         rockchip,cmd_delay = <0>;       
                                  };                                     
                 rockchip,on-cmds155{                                    
                                         compatible = "rockchip,on-cmds";  
                                         rockchip,cmd_type = <0x01>;     
                                         rockchip,dsi_id = <0>;          
                                         rockchip,cmd = <0x15 0x77 0x16>;
                                         rockchip,cmd_delay = <0>;       
                                  };

                 rockchip,on-cmds156{                                    
                                         compatible = "rockchip,on-cmds";  
                                         rockchip,cmd_type = <0x01>;     
                                         rockchip,dsi_id = <0>;          
                                         rockchip,cmd = <0x15 0x78 0x2C>;
                                         rockchip,cmd_delay = <0>;       
                                  };
				
		 rockchip,on-cmds157{                                    
                                         compatible = "rockchip,on-cmds";  
                                         rockchip,cmd_type = <0x01>;     
                                         rockchip,dsi_id = <0>;          
                                         rockchip,cmd = <0x15 0x79 0x28>;
                                         rockchip,cmd_delay = <0>;       
                                  };
				  
		 rockchip,on-cmds158{                                    
                                         compatible = "rockchip,on-cmds";  
                                         rockchip,cmd_type = <0x01>;     
                                         rockchip,dsi_id = <0>;          
                                         rockchip,cmd = <0x15 0x7A 0x26>;
                                         rockchip,cmd_delay = <0>;       
                                  };
				  				
		 rockchip,on-cmds159{                                    
                                         compatible = "rockchip,on-cmds";  
                                         rockchip,cmd_type = <0x01>;     
                                         rockchip,dsi_id = <0>;          
                                         rockchip,cmd = <0x15 0x7B 0x42>;
                                         rockchip,cmd_delay = <0>;       
                                  };
				  				
		 rockchip,on-cmds160{                                    
                                         compatible = "rockchip,on-cmds";  
                                         rockchip,cmd_type = <0x01>;     
                                         rockchip,dsi_id = <0>;          
                                         rockchip,cmd = <0x15 0x7C 0x30>;
                                         rockchip,cmd_delay = <0>;       
                                  };
				  				
		 rockchip,on-cmds161{                                    
                                         compatible = "rockchip,on-cmds";  
                                         rockchip,cmd_type = <0x01>;     
                                         rockchip,dsi_id = <0>;          
                                         rockchip,cmd = <0x15 0x7D 0x38>;
                                         rockchip,cmd_delay = <0>;       
                                  };
				  				
		 rockchip,on-cmds162{                                    
                                         compatible = "rockchip,on-cmds";  
                                         rockchip,cmd_type = <0x01>;     
                                         rockchip,dsi_id = <0>;          
                                         rockchip,cmd = <0x15 0x7E 0x29>;
                                         rockchip,cmd_delay = <0>;       
                                  };
				  				
		 rockchip,on-cmds163{                                    
                                         compatible = "rockchip,on-cmds";  
                                         rockchip,cmd_type = <0x01>;     
                                         rockchip,dsi_id = <0>;          
                                         rockchip,cmd = <0x15 0x7F 0x26>;
                                         rockchip,cmd_delay = <0>;       
                                  };
				  				
		 rockchip,on-cmds164{                                    
                                         compatible = "rockchip,on-cmds";  
                                         rockchip,cmd_type = <0x01>;     
                                         rockchip,dsi_id = <0>;          
                                         rockchip,cmd = <0x15 0x80 0x1C>;
                                         rockchip,cmd_delay = <0>;       
                                  };
				  				
		 rockchip,on-cmds165{                                    
                                         compatible = "rockchip,on-cmds";  
                                         rockchip,cmd_type = <0x01>;     
                                         rockchip,dsi_id = <0>;          
                                         rockchip,cmd = <0x15 0x81 0x0D>;
                                         rockchip,cmd_delay = <0>;       
                                  };
				  				
		 rockchip,on-cmds166{                                    
                                         compatible = "rockchip,on-cmds";  
                                         rockchip,cmd_type = <0x01>;     
                                         rockchip,dsi_id = <0>;          
                                         rockchip,cmd = <0x15 0x82 0x00>;
                                         rockchip,cmd_delay = <0>;       
                                  };
				  				
		 rockchip,on-cmds167{                                    
                                         compatible = "rockchip,on-cmds";  
                                         rockchip,cmd_type = <0x01>;     
                                         rockchip,dsi_id = <0>;          
                                         rockchip,cmd = <0x15 0xE0 0x04>;
                                         rockchip,cmd_delay = <0>;       
                                  };
				  				
		 rockchip,on-cmds168{                                    
                                         compatible = "rockchip,on-cmds";  
                                         rockchip,cmd_type = <0x01>;     
                                         rockchip,dsi_id = <0>;          
                                         rockchip,cmd = <0x15 0x2B 0x2B>;
                                         rockchip,cmd_delay = <0>;       
                                  };
				  				
		 rockchip,on-cmds169{                                    
                                         compatible = "rockchip,on-cmds";  
                                         rockchip,cmd_type = <0x01>;     
                                         rockchip,dsi_id = <0>;          
                                         rockchip,cmd = <0x15 0x2E 0x44>;
                                         rockchip,cmd_delay = <0>;       
                                  };
				  				
		 rockchip,on-cmds170{                                    
                                         compatible = "rockchip,on-cmds";  
                                         rockchip,cmd_type = <0x01>;     
                                         rockchip,dsi_id = <0>;          
                                         rockchip,cmd = <0x15 0xE0 0x00>;
                                         rockchip,cmd_delay = <0>;       
                                  };
				  				
		 rockchip,on-cmds171{                                    
                                         compatible = "rockchip,on-cmds";  
                                         rockchip,cmd_type = <0x01>;     
                                         rockchip,dsi_id = <0>;          
                                         rockchip,cmd = <0x15 0xE6 0x02>;
                                         rockchip,cmd_delay = <0>;       
                                  };
				  				
		 rockchip,on-cmds172{                                    
                                         compatible = "rockchip,on-cmds";  
                                         rockchip,cmd_type = <0x01>;     
                                         rockchip,dsi_id = <0>;          
                                         rockchip,cmd = <0x15 0xE7 0x02>;
                                         rockchip,cmd_delay = <0>;       
                                  };
				  
			rockchip,on-cmds173 {
			compatible = "rockchip,on-cmds";
			rockchip,cmd_type = <0x01>;
			rockchip,dsi_id = <0>;
			rockchip,cmd = <0x05 0x11>; //0xff
			rockchip,cmd_delay = <120>;
			};

			rockchip,on-cmds174 {
			compatible = "rockchip,on-cmds";
			rockchip,cmd_type = <0x01>;
			rockchip,dsi_id = <0>;
			rockchip,cmd = <0x05 0x29>;
			rockchip,cmd_delay = <20>;
			};					

			};

    disp_timings: display-timings {
        native-mode = <&timing0>;
        compatible = "rockchip,display-timings";
        timing0: timing0 {
            screen-type = <SCREEN_MIPI>;
            //lvds-format = <LVDS_8BIT_2>;
            out-face    = <OUT_P888>;
            clock-frequency = <72000000>;
            hactive = <800>;
            vactive = <1280>;

            hsync-len = <18>;
            hback-porch = <18>;
            hfront-porch = <18>;

            vsync-len = <4>;
            vback-porch = <4>;
            vfront-porch = <16>;
	    screen-width = <135>;
	    screen-hight = <216>;

            hsync-active = <0>;
            vsync-active = <0>;
            de-active = <0>;
            pixelclk-active = <0>;
            swap-rb = <0>;
            swap-rg = <0>;
            swap-gb = <0>;
        };
    };
};

